# CC2756 register map
File version: 1.0
CPU: CM4 r0p4, little endian, no MPU, no FPU, VTOR, 3 interrupt priority bits
Registers are 32-bit, read-write, reset 0x0 unless marked. A register's access mark holds for its fields unless they carry their own. Offsets are from the block's base; [hi:lo] are bit positions; {n}, {i} and the like mark numbered series; 'fields as' and 'values as' point back to an identical list.

## LRFDMDM32 (part 2 of 2)
Base 0x40082400
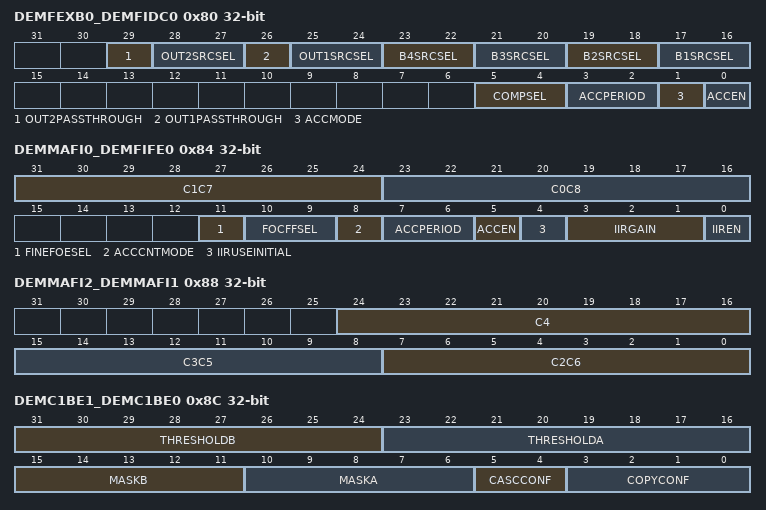
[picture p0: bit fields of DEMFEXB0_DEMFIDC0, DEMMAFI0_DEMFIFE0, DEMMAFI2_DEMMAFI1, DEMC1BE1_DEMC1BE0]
0x80 DEMFEXB0_DEMFIDC0 — Internal. Only to be used through TI provided API.
  [29] OUT2PASSTHROUGH — Internal. Only to be used through TI provided API.
    1=ONE (Internal. Only to be used through TI provided API.); 0=ZERO (Internal. Only to be used through TI provided API.)
  [28:27] OUT2SRCSEL — Internal. Only to be used through TI provided API.
    2=BDE1 (Internal. Only to be used through TI provided API.); 1=CMIX (Internal. Only to be used through TI provided API.); 0=CODC (Internal. Only to be used through TI provided API.)
  [26] OUT1PASSTHROUGH — Internal. Only to be used through TI provided API.
    values as OUT2PASSTHROUGH
  [25:24] OUT1SRCSEL — Internal. Only to be used through TI provided API.
    values as OUT2SRCSEL
  [23:22] B4SRCSEL — Internal. Only to be used through TI provided API.
    3=ONES (Internal. Only to be used through TI provided API.); 0=ZEROS (Internal. Only to be used through TI provided API.)
  [21:20] B3SRCSEL — Internal. Only to be used through TI provided API.
    2=CMIX (Internal. Only to be used through TI provided API.); 1=CODC (Internal. Only to be used through TI provided API.); 0=INPUT (Internal. Only to be used through TI provided API.)
  [19:18] B2SRCSEL — Internal. Only to be used through TI provided API.
    2=BDE1 (Internal. Only to be used through TI provided API.); 1=CODC (Internal. Only to be used through TI provided API.); 0=INPUT (Internal. Only to be used through TI provided API.)
  [17:16] B1SRCSEL — Internal. Only to be used through TI provided API.
    2=BDE1 (Internal. Only to be used through TI provided API.); 1=CMIX (Internal. Only to be used through TI provided API.); 0=INPUT (Internal. Only to be used through TI provided API.)
  [5:4] COMPSEL — Internal. Only to be used through TI provided API.
    2=ACC (Internal. Only to be used through TI provided API.); 0=MANUAL (Internal. Only to be used through TI provided API.)
  [3:2] ACCPERIOD — Internal. Only to be used through TI provided API.
    3=SMPL512 (Internal. Only to be used through TI provided API.); 2=SMPL128 (Internal. Only to be used through TI provided API.); 1=SMPL32 (Internal. Only to be used through TI provided API.); 0=SMPL8 (Internal. Only to be used through TI provided API.)
  [1] ACCMODE — Internal. Only to be used through TI provided API.
    1=CONT (Internal. Only to be used through TI provided API.); 0=SINGLE (Internal. Only to be used through TI provided API.)
  [0] ACCEN — Internal. Only to be used through TI provided API.
    1=ON (Internal. Only to be used through TI provided API.); 0=OFF (Internal. Only to be used through TI provided API.)
0x84 DEMMAFI0_DEMFIFE0 — Internal. Only to be used through TI provided API.
  [31:24] C1C7 — Internal. Only to be used through TI provided API.
    255=ALLONES (Internal. Only to be used through TI provided API.); 0=ALLZEROS (Internal. Only to be used through TI provided API.)
  [23:16] C0C8 — Internal. Only to be used through TI provided API.
    values as C1C7
  [11] FINEFOESEL — Internal. Only to be used through TI provided API.
    1=ACC (Internal. Only to be used through TI provided API.); 0=IIR (Internal. Only to be used through TI provided API.)
  [10:9] FOCFFSEL — Internal. Only to be used through TI provided API.
    2=MANUAL (Internal. Only to be used through TI provided API.); 1=ACC (Internal. Only to be used through TI provided API.); 0=IIR (Internal. Only to be used through TI provided API.)
  [8] ACCCNTMODE — Internal. Only to be used through TI provided API.
    values as DEMFEXB0_DEMFIDC0.ACCMODE
  [7:6] ACCPERIOD — Internal. Only to be used through TI provided API.
    3=PER512 (Internal. Only to be used through TI provided API.); 2=PER256 (Internal. Only to be used through TI provided API.); 1=PER128 (Internal. Only to be used through TI provided API.); 0=PER64 (Internal. Only to be used through TI provided API.)
  [5] ACCEN — Internal. Only to be used through TI provided API.
    values as DEMFEXB0_DEMFIDC0.ACCEN
  [4] IIRUSEINITIAL — Internal. Only to be used through TI provided API.
    1=EN (Internal. Only to be used through TI provided API.); 0=DIS (Internal. Only to be used through TI provided API.)
  [3:1] IIRGAIN — Internal. Only to be used through TI provided API.
    7=DIV1024 (Internal. Only to be used through TI provided API.); 6=DIV512 (Internal. Only to be used through TI provided API.); 5=DIV256 (Internal. Only to be used through TI provided API.); 4=DIV128 (Internal. Only to be used through TI provided API.); 3=DIV64 (Internal. Only to be used through TI provided API.); 2=DIV32 (Internal. Only to be used through TI provided API.); 1=DIV16 (Internal. Only to be used through TI provided API.); 0=OFF (Internal. Only to be used through TI provided API.)
  [0] IIREN — Internal. Only to be used through TI provided API.
    values as DEMFEXB0_DEMFIDC0.ACCEN
0x88 DEMMAFI2_DEMMAFI1 — Internal. Only to be used through TI provided API.
  [24:16] C4 — Internal. Only to be used through TI provided API.
    0x1FF=ALLONES (Internal. Only to be used through TI provided API.); 0=ALLZEROS (Internal. Only to be used through TI provided API.)
  [15:8] C3C5 — Internal. Only to be used through TI provided API.
    values as DEMMAFI0_DEMFIFE0.C1C7
  [7:0] C2C6 — Internal. Only to be used through TI provided API.
    values as DEMMAFI0_DEMFIFE0.C1C7
0x8C DEMC1BE1_DEMC1BE0 — Internal. Only to be used through TI provided API.
  [31:24] THRESHOLDB — Internal. Only to be used through TI provided API.
    values as DEMMAFI0_DEMFIFE0.C1C7
  [23:16] THRESHOLDA — Internal. Only to be used through TI provided API.
    values as DEMMAFI0_DEMFIFE0.C1C7
  [15:11] MASKB — Internal. Only to be used through TI provided API.
    31=ALLONES (Internal. Only to be used through TI provided API.); 0=ALLZEROS (Internal. Only to be used through TI provided API.)
  [10:6] MASKA — Internal. Only to be used through TI provided API.
    values as MASKB
  [5:4] CASCCONF — Internal. Only to be used through TI provided API.
    2=PARALLEL (Internal. Only to be used through TI provided API.); 1=SERIAL (Internal. Only to be used through TI provided API.); 0=SINGLE (Internal. Only to be used through TI provided API.)
  [3:0] COPYCONF — Internal. Only to be used through TI provided API.
    15=ALLONES (Internal. Only to be used through TI provided API.); 0=ALLZEROS (Internal. Only to be used through TI provided API.)
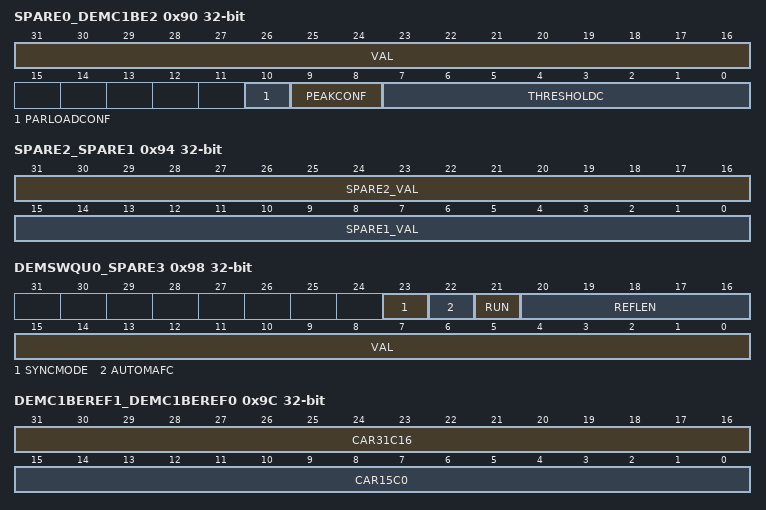
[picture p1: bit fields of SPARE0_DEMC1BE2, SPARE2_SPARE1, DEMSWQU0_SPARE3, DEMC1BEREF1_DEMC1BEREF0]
0x90 SPARE0_DEMC1BE2 — Internal. Only to be used through TI provided API.
  [31:16] VAL — Internal. Only to be used through TI provided API.
    0xFFFF=ALLONES (Internal. Only to be used through TI provided API.); 0=ALLZEROS (Internal. Only to be used through TI provided API.)
  [10] PARLOADCONF — Internal. Only to be used through TI provided API.
    1=ATOD (Internal. Only to be used through TI provided API.); 0=ATOB (Internal. Only to be used through TI provided API.)
  [9:8] PEAKCONF — Internal. Only to be used through TI provided API.
    2=BESTAB (Internal. Only to be used through TI provided API.); 1=BEST (Internal. Only to be used through TI provided API.); 0=THRESH (Internal. Only to be used through TI provided API.)
  [7:0] THRESHOLDC — Internal. Only to be used through TI provided API.
    values as DEMMAFI0_DEMFIFE0.C1C7
0x94 SPARE2_SPARE1 — Internal. Only to be used through TI provided API.
  [31:16] SPARE2_VAL — Internal. Only to be used through TI provided API.
    values as SPARE0_DEMC1BE2.VAL
  [15:0] SPARE1_VAL — Internal. Only to be used through TI provided API.
    values as SPARE0_DEMC1BE2.VAL
0x98 DEMSWQU0_SPARE3 — Internal. Only to be used through TI provided API.
  [23] SYNCMODE — Internal. Only to be used through TI provided API.
    values as DEMFEXB0_DEMFIDC0.OUT2PASSTHROUGH
  [22] AUTOMAFC — Internal. Only to be used through TI provided API.
    values as DEMFEXB0_DEMFIDC0.ACCEN
  [21] RUN — Internal. Only to be used through TI provided API.
    values as DEMFEXB0_DEMFIDC0.ACCEN
  [20:16] REFLEN — Internal. Only to be used through TI provided API.
    values as DEMC1BE1_DEMC1BE0.MASKB
  [15:0] VAL — Internal. Only to be used through TI provided API.
    values as SPARE0_DEMC1BE2.VAL
0x9C DEMC1BEREF1_DEMC1BEREF0 — Internal. Only to be used through TI provided API.
  [31:16] CAR31C16 — Internal. Only to be used through TI provided API.
    values as SPARE0_DEMC1BE2.VAL
  [15:0] CAR15C0 — Internal. Only to be used through TI provided API.
    values as SPARE0_DEMC1BE2.VAL
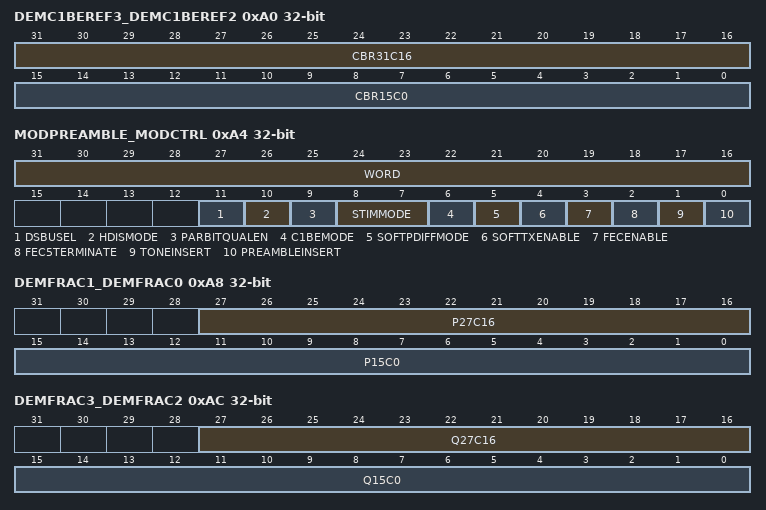
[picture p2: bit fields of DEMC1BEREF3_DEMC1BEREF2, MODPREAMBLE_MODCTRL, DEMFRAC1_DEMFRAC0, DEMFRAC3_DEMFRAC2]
0xA0 DEMC1BEREF3_DEMC1BEREF2 — Internal. Only to be used through TI provided API.
  [31:16] CBR31C16 — Internal. Only to be used through TI provided API.
    values as SPARE0_DEMC1BE2.VAL
  [15:0] CBR15C0 — Internal. Only to be used through TI provided API.
    values as SPARE0_DEMC1BE2.VAL
0xA4 MODPREAMBLE_MODCTRL — Internal. Only to be used through TI provided API.
  [31:16] WORD — Internal. Only to be used through TI provided API.
    values as SPARE0_DEMC1BE2.VAL
  [11] DSBUSEL — Internal. Only to be used through TI provided API.
    values as DEMFEXB0_DEMFIDC0.OUT2PASSTHROUGH
  [10] HDISMODE — Internal. Only to be used through TI provided API.
    values as DEMMAFI0_DEMFIFE0.IIRUSEINITIAL
  [9] PARBITQUALEN — Internal. Only to be used through TI provided API.
    values as DEMFEXB0_DEMFIDC0.ACCEN
  [8:7] STIMMODE — Internal. Only to be used through TI provided API.
    2=EARLY (Internal. Only to be used through TI provided API.); 1=LATE (Internal. Only to be used through TI provided API.); 0=NORMAL (Internal. Only to be used through TI provided API.)
  [6] C1BEMODE — Internal. Only to be used through TI provided API.
    1=EARLYLATE (Internal. Only to be used through TI provided API.); 0=NORMAL (Internal. Only to be used through TI provided API.)
  [5] SOFTPDIFFMODE — Internal. Only to be used through TI provided API.
    values as DEMMAFI0_DEMFIFE0.IIRUSEINITIAL
  [4] SOFTTXENABLE — Internal. Only to be used through TI provided API.
    values as DEMFEXB0_DEMFIDC0.ACCEN
  [3] FECENABLE — Internal. Only to be used through TI provided API.
    values as DEMFEXB0_DEMFIDC0.ACCEN
  [2] FEC5TERMINATE — Internal. Only to be used through TI provided API.
    values as DEMFEXB0_DEMFIDC0.ACCEN
  [1] TONEINSERT — Internal. Only to be used through TI provided API.
    values as DEMMAFI0_DEMFIFE0.IIRUSEINITIAL
  [0] PREAMBLEINSERT — Internal. Only to be used through TI provided API.
    values as DEMMAFI0_DEMFIFE0.IIRUSEINITIAL
0xA8 DEMFRAC1_DEMFRAC0 — Internal. Only to be used through TI provided API.
  [27:16] P27C16 — Internal. Only to be used through TI provided API.
    0xFFF=ALLONES (Internal. Only to be used through TI provided API.); 0=ALLZEROS (Internal. Only to be used through TI provided API.)
  [15:0] P15C0 — Internal. Only to be used through TI provided API.
    values as SPARE0_DEMC1BE2.VAL
0xAC DEMFRAC3_DEMFRAC2 — Internal. Only to be used through TI provided API.
  [27:16] Q27C16 — Internal. Only to be used through TI provided API.
    values as DEMFRAC1_DEMFRAC0.P27C16
  [15:0] Q15C0 — Internal. Only to be used through TI provided API.
    values as SPARE0_DEMC1BE2.VAL
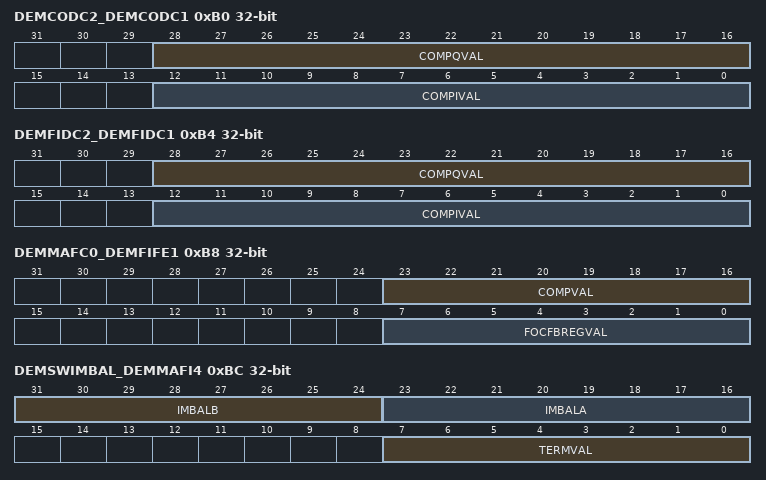
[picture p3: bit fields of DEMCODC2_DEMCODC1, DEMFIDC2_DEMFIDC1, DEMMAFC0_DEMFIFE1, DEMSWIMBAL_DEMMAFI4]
0xB0 DEMCODC2_DEMCODC1 — Internal. Only to be used through TI provided API.
  [28:16] COMPQVAL — Internal. Only to be used through TI provided API.
    0x1FFF=ALLONES (Internal. Only to be used through TI provided API.); 0=ALLZEROS (Internal. Only to be used through TI provided API.)
  [12:0] COMPIVAL — Internal. Only to be used through TI provided API.
    values as COMPQVAL
0xB4 DEMFIDC2_DEMFIDC1 — Internal. Only to be used through TI provided API.
  fields as DEMCODC2_DEMCODC1
0xB8 DEMMAFC0_DEMFIFE1 — Internal. Only to be used through TI provided API.
  [23:16] COMPVAL — Internal. Only to be used through TI provided API.
    values as DEMMAFI0_DEMFIFE0.C1C7
  [7:0] FOCFBREGVAL — Internal. Only to be used through TI provided API.
    values as DEMMAFI0_DEMFIFE0.C1C7
0xBC DEMSWIMBAL_DEMMAFI4 — Internal. Only to be used through TI provided API.
  [all] fields
    values as DEMMAFI0_DEMFIFE0.C1C7
  [31:24] IMBALB — Internal. Only to be used through TI provided API.
  [23:16] IMBALA — Internal. Only to be used through TI provided API.
  [7:0] TERMVAL — Internal. Only to be used through TI provided API.
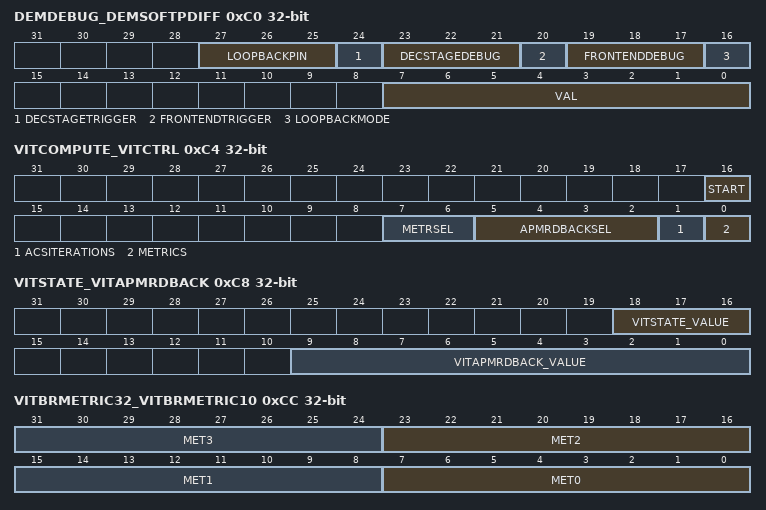
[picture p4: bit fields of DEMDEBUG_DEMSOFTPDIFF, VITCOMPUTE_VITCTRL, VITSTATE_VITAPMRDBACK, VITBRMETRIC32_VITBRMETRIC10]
0xC0 DEMDEBUG_DEMSOFTPDIFF — Internal. Only to be used through TI provided API.
  [27:25] LOOPBACKPIN — Internal. Only to be used through TI provided API.
    {v}=GPI{v} (Internal. Only to be used through TI provided API.) (v=0..7)
  [24] DECSTAGETRIGGER — Internal. Only to be used through TI provided API.
    values as DEMFEXB0_DEMFIDC0.OUT2PASSTHROUGH
  [23:21] DECSTAGEDEBUG — Internal. Only to be used through TI provided API.
    7=SOFD (Internal. Only to be used through TI provided API.); 6=STIM (Internal. Only to be used through TI provided API.); 5=MAFC (Internal. Only to be used through TI provided API.); 4=C1BE (Internal. Only to be used through TI provided API.); 3=MAFI (Internal. Only to be used through TI provided API.); 2=FIFE (Internal. Only to be used through TI provided API.); 1=PDIF (Internal. Only to be used through TI provided API.); 0=NOSEL (Internal. Only to be used through TI provided API.)
  [20] FRONTENDTRIGGER — Internal. Only to be used through TI provided API.
    values as DEMFEXB0_DEMFIDC0.OUT2PASSTHROUGH
  [19:17] FRONTENDDEBUG — Internal. Only to be used through TI provided API.
    7=FIDC (Internal. Only to be used through TI provided API.); 6=FRAC (Internal. Only to be used through TI provided API.); 5=CHFI (Internal. Only to be used through TI provided API.); 4=BDE2 (Internal. Only to be used through TI provided API.); 3=FEXB2 (Internal. Only to be used through TI provided API.); 2=BDE1 (Internal. Only to be used through TI provided API.); 1=IQMC (Internal. Only to be used through TI provided API.); 0=NOSEL (Internal. Only to be used through TI provided API.)
  [16] LOOPBACKMODE — Internal. Only to be used through TI provided API.
    values as DEMFEXB0_DEMFIDC0.OUT2PASSTHROUGH
  [7:0] VAL — Internal. Only to be used through TI provided API.
    values as DEMMAFI0_DEMFIFE0.C1C7
0xC4 VITCOMPUTE_VITCTRL — Internal. Only to be used through TI provided API.
  [16] START wo — Internal. Only to be used through TI provided API.
    values as DEMFEXB0_DEMFIDC0.OUT2PASSTHROUGH
  [7:6] METRSEL — Internal. Only to be used through TI provided API.
    3=MLSE (Internal. Only to be used through TI provided API.); 2=SOFD (Internal. Only to be used through TI provided API.); 1=PHAC (Internal. Only to be used through TI provided API.); 0=MET5M (Internal. Only to be used through TI provided API.)
  [5:2] APMRDBACKSEL — Internal. Only to be used through TI provided API.
    {v}=APM{v-8} (Internal. Only to be used through TI provided API.) (v=8..15); 0=NOSEL (Internal. Only to be used through TI provided API.)
  [1] ACSITERATIONS — Internal. Only to be used through TI provided API.
    1=CODE23 (Internal. Only to be used through TI provided API.); 0=CODE12 (Internal. Only to be used through TI provided API.)
  [0] METRICS — Internal. Only to be used through TI provided API.
    1=SOFT (Internal. Only to be used through TI provided API.); 0=HW (Internal. Only to be used through TI provided API.)
0xC8 VITSTATE_VITAPMRDBACK ro — Internal. Only to be used through TI provided API.
  [18:16] VITSTATE_VALUE — Internal. Only to be used through TI provided API.
    7=ALLONES (Internal. Only to be used through TI provided API.); 0=ALLZEROS (Internal. Only to be used through TI provided API.)
  [9:0] VITAPMRDBACK_VALUE — Internal. Only to be used through TI provided API.
    0x3FF=ALLONES (Internal. Only to be used through TI provided API.); 0=ALLZEROS (Internal. Only to be used through TI provided API.)
0xCC VITBRMETRIC32_VITBRMETRIC10 — Internal. Only to be used through TI provided API.
  [all] fields
    values as DEMMAFI0_DEMFIFE0.C1C7
  [8n+7:8n] MET{n} (n=0..3) — Internal. Only to be used through TI provided API.
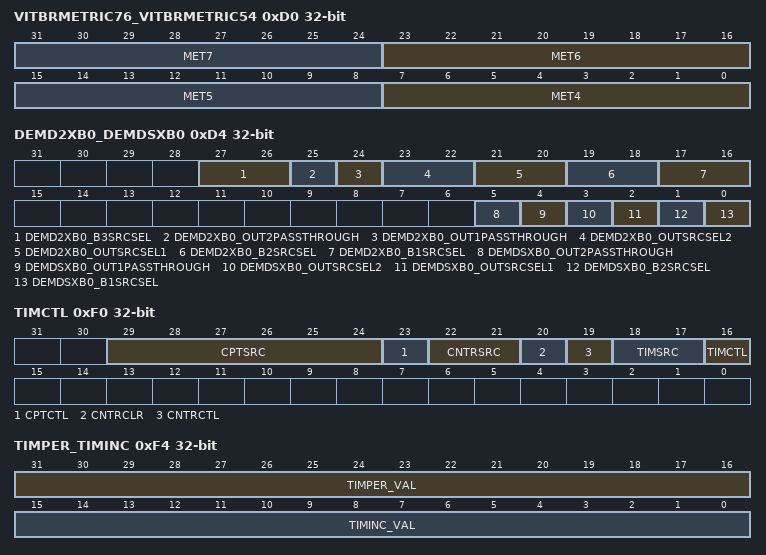
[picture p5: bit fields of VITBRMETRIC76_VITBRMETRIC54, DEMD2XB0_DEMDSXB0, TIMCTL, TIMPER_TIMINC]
0xD0 VITBRMETRIC76_VITBRMETRIC54 — Internal. Only to be used through TI provided API.
  [all] fields
    values as DEMMAFI0_DEMFIFE0.C1C7
  [8n-25:8n-32] MET{n} (n=4..7) — Internal. Only to be used through TI provided API.
0xD4 DEMD2XB0_DEMDSXB0 — Internal. Only to be used through TI provided API.
  [27:26] DEMD2XB0_B3SRCSEL — Internal. Only to be used through TI provided API.
    2=STIM (Internal. Only to be used through TI provided API.); 1=MAFC (Internal. Only to be used through TI provided API.); 0=INPUT (Internal. Only to be used through TI provided API.)
  [25] DEMD2XB0_OUT2PASSTHROUGH — Internal. Only to be used through TI provided API.
  [24] DEMD2XB0_OUT1PASSTHROUGH — Internal. Only to be used through TI provided API.
  [23:22] DEMD2XB0_OUTSRCSEL2 — Internal. Only to be used through TI provided API.
    2=PDIF2 (Internal. Only to be used through TI provided API.); 1=STIM (Internal. Only to be used through TI provided API.); 0=MAFC (Internal. Only to be used through TI provided API.)
  [21:20] DEMD2XB0_OUTSRCSEL1 — Internal. Only to be used through TI provided API.
    values as DEMD2XB0_OUTSRCSEL2
  [19:18] DEMD2XB0_B2SRCSEL — Internal. Only to be used through TI provided API.
    2=PDIF2 (Internal. Only to be used through TI provided API.); 1=MAFC (Internal. Only to be used through TI provided API.); 0=INPUT (Internal. Only to be used through TI provided API.)
  [17:16] DEMD2XB0_B1SRCSEL — Internal. Only to be used through TI provided API.
    2=PDIF2 (Internal. Only to be used through TI provided API.); 1=STIM (Internal. Only to be used through TI provided API.); 0=INPUT (Internal. Only to be used through TI provided API.)
  [5] DEMDSXB0_OUT2PASSTHROUGH — Internal. Only to be used through TI provided API.
    values as DEMFEXB0_DEMFIDC0.OUT2PASSTHROUGH
  [4] DEMDSXB0_OUT1PASSTHROUGH — Internal. Only to be used through TI provided API.
    values as DEMFEXB0_DEMFIDC0.OUT2PASSTHROUGH
  [3] DEMDSXB0_OUTSRCSEL2 — Internal. Only to be used through TI provided API.
    1=MAFI (Internal. Only to be used through TI provided API.); 0=FIFE (Internal. Only to be used through TI provided API.)
  [2] DEMDSXB0_OUTSRCSEL1 — Internal. Only to be used through TI provided API.
    values as DEMDSXB0_OUTSRCSEL2
  [1] DEMDSXB0_B2SRCSEL — Internal. Only to be used through TI provided API.
    1=FIFE (Internal. Only to be used through TI provided API.); 0=INPUT (Internal. Only to be used through TI provided API.)
  [0] DEMDSXB0_B1SRCSEL — Internal. Only to be used through TI provided API.
    1=MAFI (Internal. Only to be used through TI provided API.); 0=INPUT (Internal. Only to be used through TI provided API.)
0xF0 TIMCTL — Internal. Only to be used through TI provided API.
  [29:24] CPTSRC — Internal. Only to be used through TI provided API.
    63=ALLONES (Internal. Only to be used through TI provided API.); 0=ALLZEROS (Internal. Only to be used through TI provided API.)
  [23] CPTCTL — Internal. Only to be used through TI provided API.
    values as DEMMAFI0_DEMFIFE0.IIRUSEINITIAL
  [22:21] CNTRSRC — Internal. Only to be used through TI provided API.
    3=CLK4BAUDF (Internal. Only to be used through TI provided API.); 2=CLK4BAUD (Internal. Only to be used through TI provided API.); 1=CLKBAUD (Internal. Only to be used through TI provided API.); 0=CLK (Internal. Only to be used through TI provided API.)
  [20] CNTRCLR — Internal. Only to be used through TI provided API.
    values as DEMFEXB0_DEMFIDC0.OUT2PASSTHROUGH
  [19] CNTRCTL — Internal. Only to be used through TI provided API.
    values as DEMFEXB0_DEMFIDC0.OUT2PASSTHROUGH
  [18:17] TIMSRC — Internal. Only to be used through TI provided API.
    values as CNTRSRC
  [16] TIMCTL — Internal. Only to be used through TI provided API.
    values as DEMMAFI0_DEMFIFE0.IIRUSEINITIAL
0xF4 TIMPER_TIMINC — Internal. Only to be used through TI provided API.
  [31:16] TIMPER_VAL — Internal. Only to be used through TI provided API.
    values as SPARE0_DEMC1BE2.VAL
  [15:0] TIMINC_VAL — Internal. Only to be used through TI provided API.
    values as SPARE0_DEMC1BE2.VAL
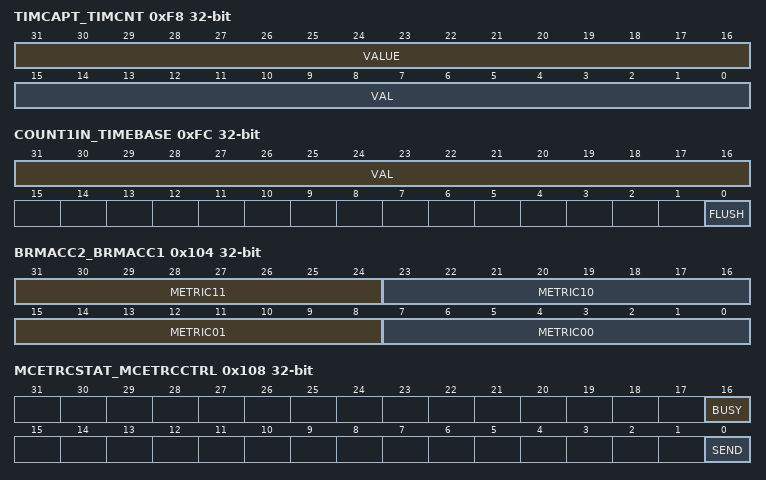
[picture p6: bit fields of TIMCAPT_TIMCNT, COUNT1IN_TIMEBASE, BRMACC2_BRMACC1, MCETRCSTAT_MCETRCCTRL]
0xF8 TIMCAPT_TIMCNT ro — Internal. Only to be used through TI provided API.
  [31:16] VALUE — Internal. Only to be used through TI provided API.
    values as SPARE0_DEMC1BE2.VAL
  [15:0] VAL — Internal. Only to be used through TI provided API.
    values as SPARE0_DEMC1BE2.VAL
0xFC COUNT1IN_TIMEBASE wo — Internal. Only to be used through TI provided API.
  [31:16] VAL — Internal. Only to be used through TI provided API.
    values as SPARE0_DEMC1BE2.VAL
  [0] FLUSH — Internal. Only to be used through TI provided API.
    values as DEMFEXB0_DEMFIDC0.OUT2PASSTHROUGH
0x100 COUNT1RES ro — Internal. Only to be used through TI provided API.
  [4:0] VAL
    values as DEMC1BE1_DEMC1BE0.MASKB
0x104 BRMACC2_BRMACC1 ro — Internal. Only to be used through TI provided API.
  [all] fields
    values as DEMMAFI0_DEMFIFE0.C1C7
  [31:24] METRIC11 — Internal. Only to be used through TI provided API.
  [23:16] METRIC10 — Internal. Only to be used through TI provided API.
  [15:8] METRIC01 — Internal. Only to be used through TI provided API.
  [7:0] METRIC00 — Internal. Only to be used through TI provided API.
0x108 MCETRCSTAT_MCETRCCTRL wo — Internal. Only to be used through TI provided API.
  [16] BUSY ro — Internal. Only to be used through TI provided API.
    values as DEMFEXB0_DEMFIDC0.OUT2PASSTHROUGH
  [0] SEND — Internal. Only to be used through TI provided API.
    values as DEMFEXB0_DEMFIDC0.OUT2PASSTHROUGH
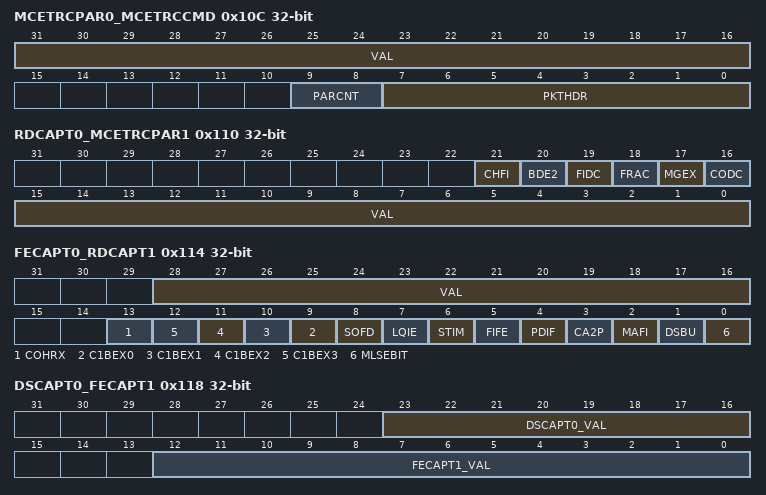
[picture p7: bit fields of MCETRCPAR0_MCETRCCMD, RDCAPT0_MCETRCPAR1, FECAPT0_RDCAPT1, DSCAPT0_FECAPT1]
0x10C MCETRCPAR0_MCETRCCMD — Internal. Only to be used through TI provided API.
  [31:16] VAL — Internal. Only to be used through TI provided API.
    values as SPARE0_DEMC1BE2.VAL
  [9:8] PARCNT — Internal. Only to be used through TI provided API.
    3=ALLONES (Internal. Only to be used through TI provided API.); 0=ALLZEROS (Internal. Only to be used through TI provided API.)
  [7:0] PKTHDR — Internal. Only to be used through TI provided API.
    values as DEMMAFI0_DEMFIFE0.C1C7
0x110 RDCAPT0_MCETRCPAR1 — Internal. Only to be used through TI provided API.
  [21] CHFI wo — Internal. Only to be used through TI provided API.
    values as DEMFEXB0_DEMFIDC0.OUT2PASSTHROUGH
  [20] BDE2 wo — Internal. Only to be used through TI provided API.
    values as DEMFEXB0_DEMFIDC0.OUT2PASSTHROUGH
  [19] FIDC wo — Internal. Only to be used through TI provided API.
    values as DEMFEXB0_DEMFIDC0.OUT2PASSTHROUGH
  [18] FRAC wo — Internal. Only to be used through TI provided API.
    values as DEMFEXB0_DEMFIDC0.OUT2PASSTHROUGH
  [17] MGEX wo — Internal. Only to be used through TI provided API.
    values as DEMFEXB0_DEMFIDC0.OUT2PASSTHROUGH
  [16] CODC wo — Internal. Only to be used through TI provided API.
    values as DEMFEXB0_DEMFIDC0.OUT2PASSTHROUGH
  [15:0] VAL — Internal. Only to be used through TI provided API.
    values as SPARE0_DEMC1BE2.VAL
0x114 FECAPT0_RDCAPT1 wo — Internal. Only to be used through TI provided API.
  [28:16] VAL — Internal. Only to be used through TI provided API.
    values as DEMCODC2_DEMCODC1.COMPQVAL
  [13] COHRX — Internal. Only to be used through TI provided API.
    values as DEMFEXB0_DEMFIDC0.OUT2PASSTHROUGH
  [n+9] C1BEX{n} (n=0..3) — Internal. Only to be used through TI provided API.
    values as DEMFEXB0_DEMFIDC0.OUT2PASSTHROUGH
  [8] SOFD — Internal. Only to be used through TI provided API.
    values as DEMFEXB0_DEMFIDC0.OUT2PASSTHROUGH
  [7] LQIE — Internal. Only to be used through TI provided API.
    values as DEMFEXB0_DEMFIDC0.OUT2PASSTHROUGH
  [6] STIM — Internal. Only to be used through TI provided API.
    values as DEMFEXB0_DEMFIDC0.OUT2PASSTHROUGH
  [5] FIFE — Internal. Only to be used through TI provided API.
    values as DEMFEXB0_DEMFIDC0.OUT2PASSTHROUGH
  [4] PDIF — Internal. Only to be used through TI provided API.
    values as DEMFEXB0_DEMFIDC0.OUT2PASSTHROUGH
  [3] CA2P — Internal. Only to be used through TI provided API.
    values as DEMFEXB0_DEMFIDC0.OUT2PASSTHROUGH
  [2] MAFI — Internal. Only to be used through TI provided API.
    values as DEMFEXB0_DEMFIDC0.OUT2PASSTHROUGH
  [1] DSBU — Internal. Only to be used through TI provided API.
    values as DEMFEXB0_DEMFIDC0.OUT2PASSTHROUGH
  [0] MLSEBIT — Internal. Only to be used through TI provided API.
    values as DEMFEXB0_DEMFIDC0.OUT2PASSTHROUGH
0x118 DSCAPT0_FECAPT1 — Internal. Only to be used through TI provided API.
  [23:16] DSCAPT0_VAL — Internal. Only to be used through TI provided API.
    values as DEMMAFI0_DEMFIFE0.C1C7
  [12:0] FECAPT1_VAL — Internal. Only to be used through TI provided API.
    values as DEMCODC2_DEMCODC1.COMPQVAL
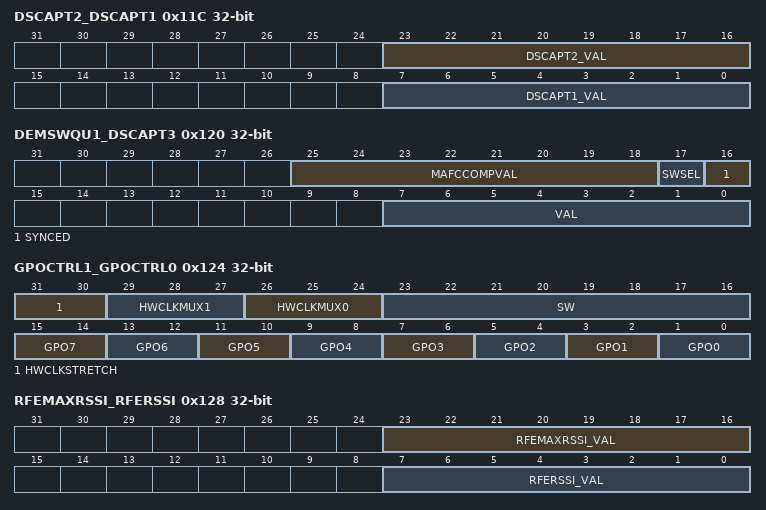
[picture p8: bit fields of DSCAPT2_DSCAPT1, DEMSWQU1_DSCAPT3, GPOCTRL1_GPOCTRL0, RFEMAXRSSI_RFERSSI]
0x11C DSCAPT2_DSCAPT1 — Internal. Only to be used through TI provided API.
  [23:16] DSCAPT2_VAL — Internal. Only to be used through TI provided API.
    values as DEMMAFI0_DEMFIFE0.C1C7
  [7:0] DSCAPT1_VAL — Internal. Only to be used through TI provided API.
    values as DEMMAFI0_DEMFIFE0.C1C7
0x120 DEMSWQU1_DSCAPT3 — Internal. Only to be used through TI provided API.
  [25:18] MAFCCOMPVAL ro — Internal. Only to be used through TI provided API.
    values as DEMMAFI0_DEMFIFE0.C1C7
  [17] SWSEL ro — Internal. Only to be used through TI provided API.
    1=B (Internal. Only to be used through TI provided API.); 0=A (Internal. Only to be used through TI provided API.)
  [16] SYNCED ro — Internal. Only to be used through TI provided API.
    values as DEMFEXB0_DEMFIDC0.OUT2PASSTHROUGH
  [7:0] VAL — Internal. Only to be used through TI provided API.
    values as DEMMAFI0_DEMFIFE0.C1C7
0x124 GPOCTRL1_GPOCTRL0 — Internal. Only to be used through TI provided API.
  [31:30] HWCLKSTRETCH — Internal. Only to be used through TI provided API.
    values as DEMFEXB0_DEMFIDC0.OUT2PASSTHROUGH
  [29:27] HWCLKMUX1 — Internal. Only to be used through TI provided API.
    values as DEMFEXB0_DEMFIDC0.OUT2PASSTHROUGH
  [26:24] HWCLKMUX0 — Internal. Only to be used through TI provided API.
    values as DEMFEXB0_DEMFIDC0.OUT2PASSTHROUGH
  [23:16] SW — Internal. Only to be used through TI provided API.
    values as DEMFEXB0_DEMFIDC0.OUT2PASSTHROUGH
  [15:14] GPO7 — Internal. Only to be used through TI provided API.
    3=THREE (Internal. Only to be used through TI provided API.); 2=TWO (Internal. Only to be used through TI provided API.); 1=TOPSM_WAIT (Internal. Only to be used through TI provided API.); 0=SW7 (Internal. Only to be used through TI provided API.)
  [13:12] GPO6 — Internal. Only to be used through TI provided API.
    3=THREE (Internal. Only to be used through TI provided API.); 2=TWO (Internal. Only to be used through TI provided API.); 1=TRANSPARENT_OUT (Internal. Only to be used through TI provided API.); 0=SW6 (Internal. Only to be used through TI provided API.)
  [11:10] GPO5 — Internal. Only to be used through TI provided API.
    3=THREE (Internal. Only to be used through TI provided API.); 2=TWO (Internal. Only to be used through TI provided API.); 1=DEM_OUT_WORD (Internal. Only to be used through TI provided API.); 0=SW5 (Internal. Only to be used through TI provided API.)
  [9:8] GPO4 — Internal. Only to be used through TI provided API.
    3=THREE (Internal. Only to be used through TI provided API.); 2=TWO (Internal. Only to be used through TI provided API.); 1=CORR_PEAK_C (Internal. Only to be used through TI provided API.); 0=SW4 (Internal. Only to be used through TI provided API.)
  [7:6] GPO3 — Internal. Only to be used through TI provided API.
    3=THREE (Internal. Only to be used through TI provided API.); 2=TWO (Internal. Only to be used through TI provided API.); 1=CORR_PEAK_B (Internal. Only to be used through TI provided API.); 0=SW3 (Internal. Only to be used through TI provided API.)
  [5:4] GPO2 — Internal. Only to be used through TI provided API.
    3=THREE (Internal. Only to be used through TI provided API.); 2=TWO (Internal. Only to be used through TI provided API.); 1=CORR_PEAK_A (Internal. Only to be used through TI provided API.); 0=SW2 (Internal. Only to be used through TI provided API.)
  [3:2] GPO1 — Internal. Only to be used through TI provided API.
    3=THREE (Internal. Only to be used through TI provided API.); 2=TWO (Internal. Only to be used through TI provided API.); 1=HWCLK1 (Internal. Only to be used through TI provided API.); 0=SW1 (Internal. Only to be used through TI provided API.)
  [1:0] GPO0 — Internal. Only to be used through TI provided API.
    3=THREE (Internal. Only to be used through TI provided API.); 2=LOOPBACK (Internal. Only to be used through TI provided API.); 1=HWCLK0 (Internal. Only to be used through TI provided API.); 0=SW0 (Internal. Only to be used through TI provided API.)
0x128 RFEMAXRSSI_RFERSSI ro — Internal. Only to be used through TI provided API.
  [23:16] RFEMAXRSSI_VAL — Internal. Only to be used through TI provided API.
    values as DEMMAFI0_DEMFIFE0.C1C7
  [7:0] RFERSSI_VAL — Internal. Only to be used through TI provided API.
    values as DEMMAFI0_DEMFIFE0.C1C7
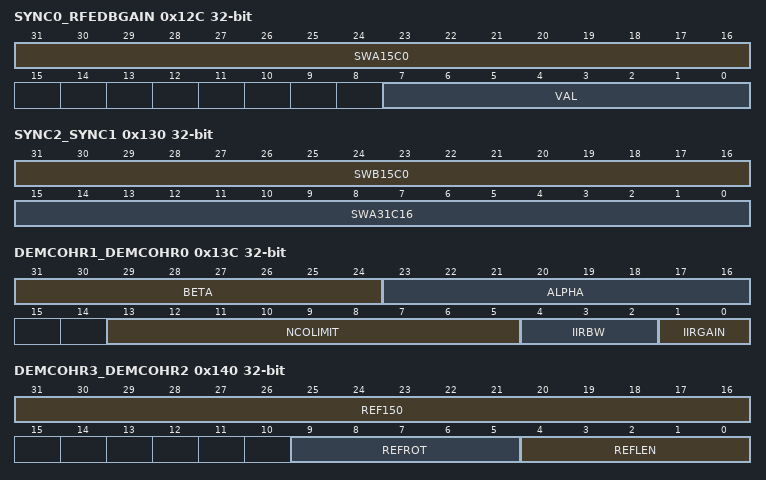
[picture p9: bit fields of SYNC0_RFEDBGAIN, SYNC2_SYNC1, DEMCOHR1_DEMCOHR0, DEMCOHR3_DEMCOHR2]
0x12C SYNC0_RFEDBGAIN ro — Internal. Only to be used through TI provided API.
  [31:16] SWA15C0 — Internal. Only to be used through TI provided API.
    values as SPARE0_DEMC1BE2.VAL
  [7:0] VAL — Internal. Only to be used through TI provided API.
    values as DEMMAFI0_DEMFIFE0.C1C7
0x130 SYNC2_SYNC1 ro — Internal. Only to be used through TI provided API.
  [31:16] SWB15C0 — Internal. Only to be used through TI provided API.
    values as SPARE0_DEMC1BE2.VAL
  [15:0] SWA31C16 — Internal. Only to be used through TI provided API.
    values as SPARE0_DEMC1BE2.VAL
0x134 SYNC3 ro — Internal. Only to be used through TI provided API.
  [15:0] SWB31C16
    values as SPARE0_DEMC1BE2.VAL
0x138 DEMHDIS0 ro — Internal. Only to be used through TI provided API.
  [23:16] VAL
0x13C DEMCOHR1_DEMCOHR0 — Internal. Only to be used through TI provided API.
  [31:24] BETA — Internal. Only to be used through TI provided API.
  [23:16] ALPHA — Internal. Only to be used through TI provided API.
  [13:5] NCOLIMIT — Internal. Only to be used through TI provided API.
  [4:2] IIRBW — Internal. Only to be used through TI provided API.
  [1:0] IIRGAIN — Internal. Only to be used through TI provided API.
0x140 DEMCOHR3_DEMCOHR2 — Internal. Only to be used through TI provided API.
  [31:16] REF150 — Internal. Only to be used through TI provided API.
  [9:5] REFROT — Internal. Only to be used through TI provided API.
  [4:0] REFLEN — Internal. Only to be used through TI provided API.
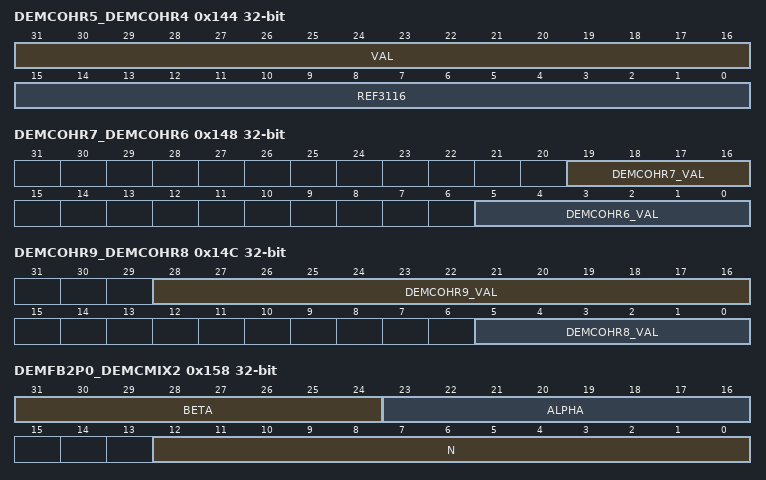
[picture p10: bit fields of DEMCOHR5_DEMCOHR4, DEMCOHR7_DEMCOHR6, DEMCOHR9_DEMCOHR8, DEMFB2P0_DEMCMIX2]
0x144 DEMCOHR5_DEMCOHR4 — Internal. Only to be used through TI provided API.
  [31:16] VAL ro — Internal. Only to be used through TI provided API.
  [15:0] REF3116 — Internal. Only to be used through TI provided API.
0x148 DEMCOHR7_DEMCOHR6 ro — Internal. Only to be used through TI provided API.
  [19:16] DEMCOHR7_VAL — Internal. Only to be used through TI provided API.
  [5:0] DEMCOHR6_VAL — Internal. Only to be used through TI provided API.
0x14C DEMCOHR9_DEMCOHR8 ro — Internal. Only to be used through TI provided API.
  [28:16] DEMCOHR9_VAL — Internal. Only to be used through TI provided API.
  [5:0] DEMCOHR8_VAL — Internal. Only to be used through TI provided API.
0x150 BAUDCOMP — Internal. Only to be used through TI provided API.
  [2:0] SCALEVAL
0x158 DEMFB2P0_DEMCMIX2 — Internal. Only to be used through TI provided API.
  [31:24] BETA — Internal. Only to be used through TI provided API.
  [23:16] ALPHA — Internal. Only to be used through TI provided API.
  [12:0] N — Internal. Only to be used through TI provided API.
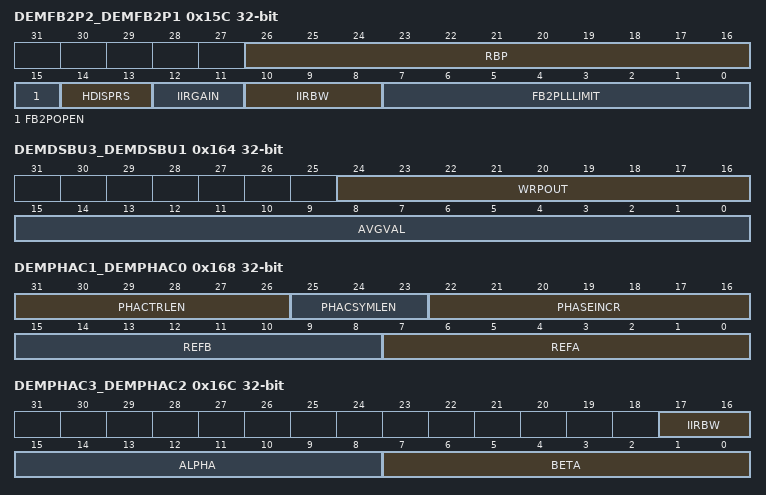
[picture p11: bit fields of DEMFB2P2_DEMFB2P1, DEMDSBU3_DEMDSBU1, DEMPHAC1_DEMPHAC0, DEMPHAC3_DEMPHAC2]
0x15C DEMFB2P2_DEMFB2P1 — Internal. Only to be used through TI provided API.
  [26:16] RBP ro — Internal. Only to be used through TI provided API.
  [15] FB2POPEN — Internal. Only to be used through TI provided API.
  [14:13] HDISPRS — Internal. Only to be used through TI provided API.
  [12:11] IIRGAIN — Internal. Only to be used through TI provided API.
  [10:8] IIRBW — Internal. Only to be used through TI provided API.
  [7:0] FB2PLLLIMIT — Internal. Only to be used through TI provided API.
0x160 DEMDSBU0 ro reset 0x1FF0000 — Internal. Only to be used through TI provided API.
  [24:16] RDPOUT
0x164 DEMDSBU3_DEMDSBU1 ro — Internal. Only to be used through TI provided API.
  [24:16] WRPOUT — Internal. Only to be used through TI provided API.
  [15:0] AVGVAL — Internal. Only to be used through TI provided API.
0x168 DEMPHAC1_DEMPHAC0 — Internal. Only to be used through TI provided API.
  [31:26] PHACTRLEN — Internal. Only to be used through TI provided API.
  [25:23] PHACSYMLEN — Internal. Only to be used through TI provided API.
  [22:16] PHASEINCR — Internal. Only to be used through TI provided API.
  [15:8] REFB — Internal. Only to be used through TI provided API.
  [7:0] REFA — Internal. Only to be used through TI provided API.
0x16C DEMPHAC3_DEMPHAC2 — Internal. Only to be used through TI provided API.
  [17:16] IIRBW — Internal. Only to be used through TI provided API.
  [15:8] ALPHA — Internal. Only to be used through TI provided API.
  [7:0] BETA — Internal. Only to be used through TI provided API.
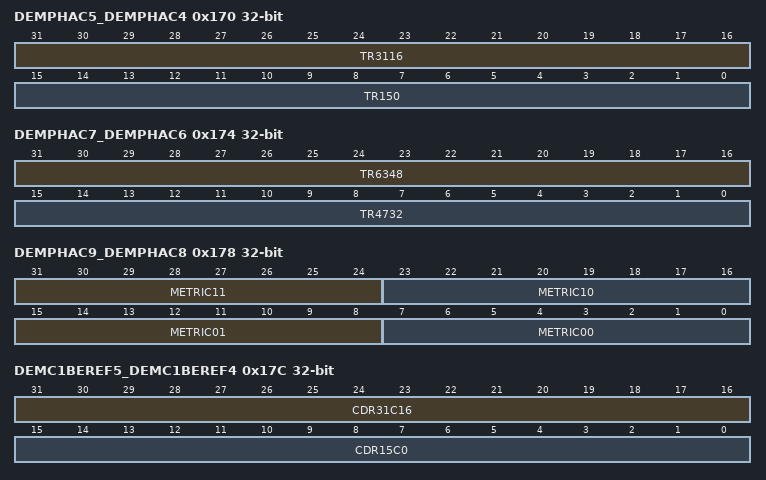
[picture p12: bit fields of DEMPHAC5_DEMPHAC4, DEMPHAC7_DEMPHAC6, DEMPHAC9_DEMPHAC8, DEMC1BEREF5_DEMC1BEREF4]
0x170 DEMPHAC5_DEMPHAC4 — Internal. Only to be used through TI provided API.
  [31:16] TR3116 — Internal. Only to be used through TI provided API.
  [15:0] TR150 — Internal. Only to be used through TI provided API.
0x174 DEMPHAC7_DEMPHAC6 — Internal. Only to be used through TI provided API.
  [31:16] TR6348 — Internal. Only to be used through TI provided API.
  [15:0] TR4732 — Internal. Only to be used through TI provided API.
0x178 DEMPHAC9_DEMPHAC8 ro — Internal. Only to be used through TI provided API.
  [31:24] METRIC11 — Internal. Only to be used through TI provided API.
  [23:16] METRIC10 — Internal. Only to be used through TI provided API.
  [15:8] METRIC01 — Internal. Only to be used through TI provided API.
  [7:0] METRIC00 — Internal. Only to be used through TI provided API.
0x17C DEMC1BEREF5_DEMC1BEREF4 — Internal. Only to be used through TI provided API.
  [31:16] CDR31C16 — Internal. Only to be used through TI provided API.
  [15:0] CDR15C0 — Internal. Only to be used through TI provided API.
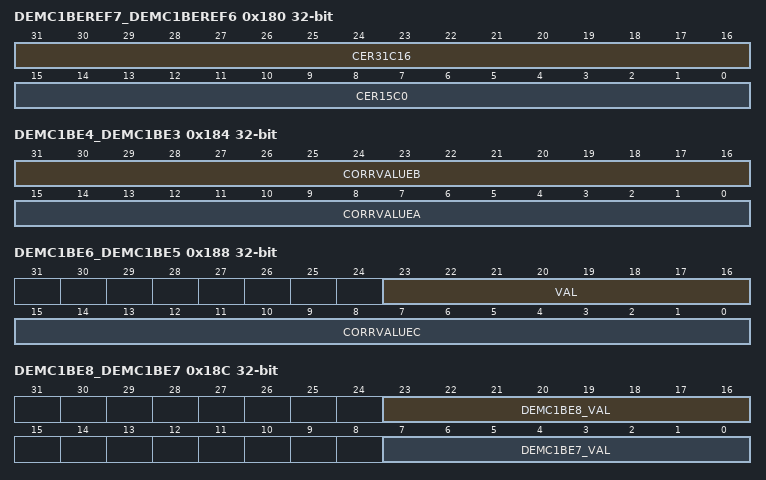
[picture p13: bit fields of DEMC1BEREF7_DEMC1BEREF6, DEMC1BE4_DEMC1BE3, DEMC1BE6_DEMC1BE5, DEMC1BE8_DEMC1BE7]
0x180 DEMC1BEREF7_DEMC1BEREF6 — Internal. Only to be used through TI provided API.
  [31:16] CER31C16 — Internal. Only to be used through TI provided API.
  [15:0] CER15C0 — Internal. Only to be used through TI provided API.
0x184 DEMC1BE4_DEMC1BE3 ro — Internal. Only to be used through TI provided API.
  [31:16] CORRVALUEB — Internal. Only to be used through TI provided API.
  [15:0] CORRVALUEA — Internal. Only to be used through TI provided API.
0x188 DEMC1BE6_DEMC1BE5 ro — Internal. Only to be used through TI provided API.
  [23:16] VAL — Internal. Only to be used through TI provided API.
  [15:0] CORRVALUEC — Internal. Only to be used through TI provided API.
0x18C DEMC1BE8_DEMC1BE7 ro — Internal. Only to be used through TI provided API.
  [23:16] DEMC1BE8_VAL — Internal. Only to be used through TI provided API.
  [7:0] DEMC1BE7_VAL — Internal. Only to be used through TI provided API.
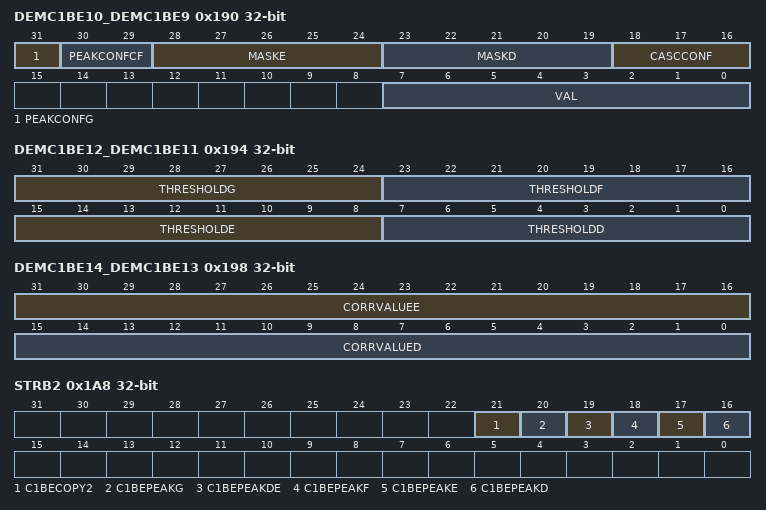
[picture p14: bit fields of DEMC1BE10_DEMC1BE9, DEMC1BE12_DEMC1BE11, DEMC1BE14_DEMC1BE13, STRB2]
0x190 DEMC1BE10_DEMC1BE9 ro — Internal. Only to be used through TI provided API.
  [31] PEAKCONFG — Internal. Only to be used through TI provided API.
  [30:29] PEAKCONFCF — Internal. Only to be used through TI provided API.
    values as SPARE0_DEMC1BE2.PEAKCONF
  [28:24] MASKE — Internal. Only to be used through TI provided API.
  [23:19] MASKD — Internal. Only to be used through TI provided API.
  [18:16] CASCCONF — Internal. Only to be used through TI provided API.
    5=SINGLE2 (Internal. Only to be used through TI provided API.); 4=SERIAL2 (Internal. Only to be used through TI provided API.); 3=SINGLE (Internal. Only to be used through TI provided API.); 2=PARALLEL (Internal. Only to be used through TI provided API.); 1=SERIAL (Internal. Only to be used through TI provided API.); 0=DISABLED (Internal. Only to be used through TI provided API.)
  [7:0] VAL — Internal. Only to be used through TI provided API.
0x194 DEMC1BE12_DEMC1BE11 — Internal. Only to be used through TI provided API.
  [31:24] THRESHOLDG — Internal. Only to be used through TI provided API.
  [23:16] THRESHOLDF — Internal. Only to be used through TI provided API.
  [15:8] THRESHOLDE — Internal. Only to be used through TI provided API.
  [7:0] THRESHOLDD — Internal. Only to be used through TI provided API.
0x198 DEMC1BE14_DEMC1BE13 ro — Internal. Only to be used through TI provided API.
  [31:16] CORRVALUEE — Internal. Only to be used through TI provided API.
  [15:0] CORRVALUED — Internal. Only to be used through TI provided API.
0x19C DEMC1BE15 ro — Internal. Only to be used through TI provided API.
  [15:0] CORRVALUEF
0x1A4 DEMC1BE20 ro — Internal. Only to be used through TI provided API.
  [31:16] CORRVALUEG
0x1A8 STRB2 wo — Internal. Only to be used through TI provided API.
  [all] fields
    values as DEMFEXB0_DEMFIDC0.OUT2PASSTHROUGH
  [21] C1BECOPY2 — Internal. Only to be used through TI provided API.
  [20] C1BEPEAKG — Internal. Only to be used through TI provided API.
  [19] C1BEPEAKDE — Internal. Only to be used through TI provided API.
  [18] C1BEPEAKF — Internal. Only to be used through TI provided API.
  [17] C1BEPEAKE — Internal. Only to be used through TI provided API.
  [16] C1BEPEAKD — Internal. Only to be used through TI provided API.
0x1AC EVTMSK3_EVT3 ro — Internal. Only to be used through TI provided API.
  [31] EVTMSK3_C1BEDLOADED — Internal. Only to be used through TI provided API.
  [30] EVTMSK3_C1BEGANY — Internal. Only to be used through TI provided API.
  [29] EVTMSK3_C1BEGNEG — Internal. Only to be used through TI provided API.
  [28] EVTMSK3_C1BEGPOS — Internal. Only to be used through TI provided API.
  [27] EVTMSK3_C1BECMBDEANY — Internal. Only to be used through TI provided API.
  [26] EVTMSK3_C1BECMBDENEG — Internal. Only to be used through TI provided API.
  [25] EVTMSK3_C1BECMBDEPOS — Internal. Only to be used through TI provided API.
  [24] EVTMSK3_C1BEFANY — Internal. Only to be used through TI provided API.
  [23] EVTMSK3_C1BEFNEG — Internal. Only to be used through TI provided API.
  [22] EVTMSK3_C1BEFPOS — Internal. Only to be used through TI provided API.
  [21] EVTMSK3_C1BEEANY — Internal. Only to be used through TI provided API.
  [20] EVTMSK3_C1BEENEG — Internal. Only to be used through TI provided API.
  [19] EVTMSK3_C1BEEPOS — Internal. Only to be used through TI provided API.
  [18] EVTMSK3_C1BEDANY — Internal. Only to be used through TI provided API.
  [17] EVTMSK3_C1BEDNEG — Internal. Only to be used through TI provided API.
  [16] EVTMSK3_C1BEDPOS — Internal. Only to be used through TI provided API.
  [15] EVT3_C1BEDLOADED — Internal. Only to be used through TI provided API.
    values as DEMFEXB0_DEMFIDC0.OUT2PASSTHROUGH
  [14] EVT3_C1BEGANY — Internal. Only to be used through TI provided API.
  [13] EVT3_C1BEGNEG — Internal. Only to be used through TI provided API.
  [12] EVT3_C1BEGPOS — Internal. Only to be used through TI provided API.
  [11] EVT3_C1BECMBDEANY — Internal. Only to be used through TI provided API.
  [10] EVT3_C1BECMBDENEG — Internal. Only to be used through TI provided API.
  [9] EVT3_C1BECMBDEPOS — Internal. Only to be used through TI provided API.
  [8] EVT3_C1BEFANY — Internal. Only to be used through TI provided API.
  [7] EVT3_C1BEFNEG — Internal. Only to be used through TI provided API.
  [6] EVT3_C1BEFPOS — Internal. Only to be used through TI provided API.
  [5] EVT3_C1BEEANY — Internal. Only to be used through TI provided API.
  [4] EVT3_C1BEENEG — Internal. Only to be used through TI provided API.
  [3] EVT3_C1BEEPOS — Internal. Only to be used through TI provided API.
  [2] EVT3_C1BEDANY — Internal. Only to be used through TI provided API.
  [1] EVT3_C1BEDNEG — Internal. Only to be used through TI provided API.
  [0] EVT3_C1BEDPOS — Internal. Only to be used through TI provided API.
0x1B0 EVTCLR3 — Internal. Only to be used through TI provided API.
  [15] C1BEDLOADED wo — Internal. Only to be used through TI provided API.
  [14] C1BEGANY wo — Internal. Only to be used through TI provided API.
  [13] C1BEGNEG wo — Internal. Only to be used through TI provided API.
  [12] C1BEGPOS wo — Internal. Only to be used through TI provided API.
  [11] C1BECMBDEANY wo — Internal. Only to be used through TI provided API.
  [10] C1BECMBDENEG wo — Internal. Only to be used through TI provided API.
  [9] C1BECMBDEPOS wo — Internal. Only to be used through TI provided API.
  [8] C1BEFANY wo — Internal. Only to be used through TI provided API.
  [7] C1BEFNEG wo — Internal. Only to be used through TI provided API.
  [6] C1BEFPOS wo — Internal. Only to be used through TI provided API.
  [5] C1BEEANY wo — Internal. Only to be used through TI provided API.
  [4] C1BEENEG wo — Internal. Only to be used through TI provided API.
  [3] C1BEEPOS wo — Internal. Only to be used through TI provided API.
  [2] C1BEDANY wo — Internal. Only to be used through TI provided API.
  [1] C1BEDNEG wo — Internal. Only to be used through TI provided API.
  [0] C1BEDPOS wo — Internal. Only to be used through TI provided API.
